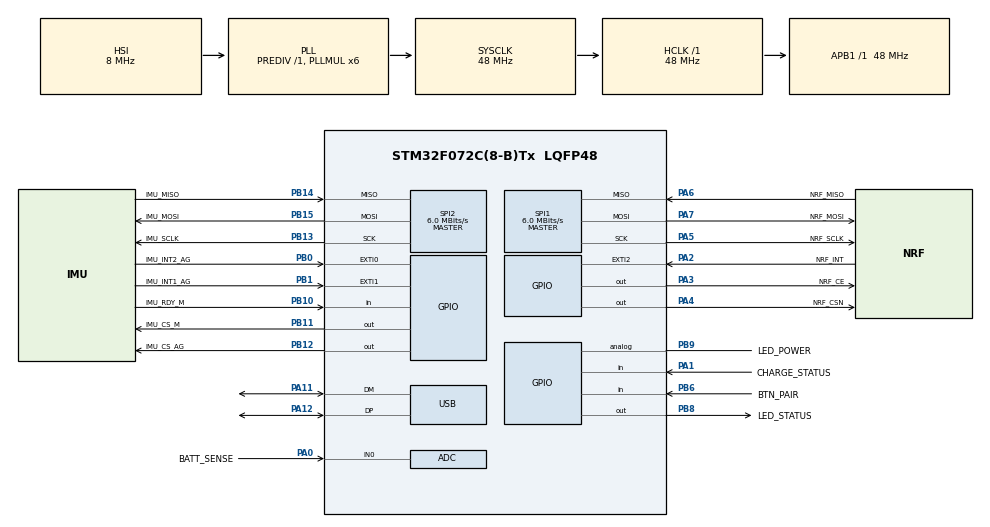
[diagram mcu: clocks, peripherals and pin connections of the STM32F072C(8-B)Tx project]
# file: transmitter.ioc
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Mcu.Family=STM32F0
Mcu.Name=STM32F072C(8-B)Tx
Mcu.Package=LQFP48
NVIC.USB_IRQn=true\:0\:0\:false\:false\:true\:false\:true
PA0.GPIO_Label=BATT_SENSE
PA0.Mode=IN0
PA0.Signal=ADC_IN0
PA1.GPIO_Label=CHARGE_STATUS
PA1.Signal=GPIO_Input
PA11.Mode=Device
PA11.Signal=USB_DM
PA12.Mode=Device
PA12.Signal=USB_DP
PA13.Mode=Serial_Wire
PA13.Signal=SYS_SWDIO
PA14.Mode=Serial_Wire
PA14.Signal=SYS_SWCLK
PA2.GPIO_Label=NRF_INT
PA2.Signal=GPXTI2
PA3.GPIO_Label=NRF_CE
PA3.Signal=GPIO_Output
PA4.GPIO_Label=NRF_CSN
PA4.Signal=GPIO_Output
PA5.GPIO_Label=NRF_SCLK
PA5.Mode=Full_Duplex_Master
PA5.Signal=SPI1_SCK
PA6.GPIO_Label=NRF_MISO
PA6.Mode=Full_Duplex_Master
PA6.Signal=SPI1_MISO
PA7.GPIO_Label=NRF_MOSI
PA7.Mode=Full_Duplex_Master
PA7.Signal=SPI1_MOSI
PB0.GPIO_Label=IMU_INT2_AG
PB0.Signal=GPXTI0
PB1.GPIO_Label=IMU_INT1_AG
PB1.Signal=GPXTI1
PB10.GPIO_Label=IMU_RDY_M
PB10.Signal=GPIO_Input
PB11.GPIO_Label=IMU_CS_M
PB11.Signal=GPIO_Output
PB12.GPIO_Label=IMU_CS_AG
PB12.Signal=GPIO_Output
PB13.GPIO_Label=IMU_SCLK
PB13.Mode=Full_Duplex_Master
PB13.Signal=SPI2_SCK
PB14.GPIO_Label=IMU_MISO
PB14.Mode=Full_Duplex_Master
PB14.Signal=SPI2_MISO
PB15.GPIO_Label=IMU_MOSI
PB15.Mode=Full_Duplex_Master
PB15.Signal=SPI2_MOSI
PB6.GPIO_Label=BTN_PAIR
PB6.GPIO_PuPd=GPIO_PULLDOWN
PB6.Signal=GPIO_Input
PB8.GPIO_Label=LED_STATUS
PB8.Signal=GPIO_Output
PB9.GPIO_Label=LED_POWER
PB9.Signal=GPIO_Analog
ProjectManager.HeapSize=0x200
ProjectManager.StackSize=0x400
ProjectManager.TargetToolchain=Other Toolchains (GPDSC)
RCC.AHBFreq_Value=48000000
RCC.APB1Freq_Value=48000000
RCC.APB1TimFreq_Value=48000000
RCC.HCLKFreq_Value=48000000
RCC.PLLMUL=RCC_PLL_MUL6
RCC.SYSCLKFreq_VALUE=48000000
RCC.SYSCLKSource=RCC_SYSCLKSOURCE_PLLCLK
RCC.VDD_VALUE=2.5
SPI1.BaudRatePrescaler=SPI_BAUDRATEPRESCALER_8
SPI1.CalculateBaudRate=6.0 MBits/s
SPI1.DataSize=SPI_DATASIZE_8BIT
SPI1.Direction=SPI_DIRECTION_2LINES
SPI1.Mode=SPI_MODE_MASTER
SPI1.VirtualType=VM_MASTER
SPI2.BaudRatePrescaler=SPI_BAUDRATEPRESCALER_8
SPI2.CalculateBaudRate=6.0 MBits/s
SPI2.DataSize=SPI_DATASIZE_8BIT
SPI2.Direction=SPI_DIRECTION_2LINES
SPI2.Mode=SPI_MODE_MASTER
SPI2.VirtualType=VM_MASTER
TIM2.Period=4294967295
TIM2.Prescaler=47
USB_DEVICE.CLASS_NAME_FS=DFU
USB_DEVICE.PID_DFU_FS=0xdf11
USB_DEVICE.VirtualMode=Dfu
USB_DEVICE.VirtualModeFS=Dfu_FS
VP_TIM2_VS_ClockSourceINT.Mode=Internal
VP_USB_DEVICE_VS_USB_DEVICE_DFU_FS.Mode=DFU_FS
board=custom

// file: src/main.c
/* USER CODE BEGIN Header */
/**
 ******************************************************************************
 * @file           : main.c
 * @brief          : Main program body
 ******************************************************************************
 * @attention
 *
 * <h2><center>&copy; Copyright (c) 2019 STMicroelectronics.
 * All rights reserved.</center></h2>
 *
 * This software component is licensed by ST under BSD 3-Clause license,
 * the "License"; You may not use this file except in compliance with the
 * License. You may obtain a copy of the License at:
 *                        opensource.org/licenses/BSD-3-Clause
 *
 ******************************************************************************
 */
/* USER CODE END Header */
#include "main.h"
#include "usb_device.h"

/* USER CODE BEGIN Includes */
#include "main_loop.hh"
/* USER CODE END Includes */

ADC_HandleTypeDef hadc;

SPI_HandleTypeDef hspi1;
SPI_HandleTypeDef hspi2;

TIM_HandleTypeDef htim2;

void        SystemClock_Config(void);
static void MX_GPIO_Init(void);
static void MX_SPI1_Init(void);
static void MX_SPI2_Init(void);
static void MX_ADC_Init(void);
static void MX_TIM2_Init(void);

/* USER CODE BEGIN 0 */
void dfu_run_bootloader()
{
  // set magic code 0xDEADBEEF
  // STM32 F072 has 16k SRAM in address 0x2000 0000 - 0x2000 3FFF
  *((unsigned long*)0x20003FF0) = 0xDEADBEEF;

  NVIC_SystemReset();
}
/* USER CODE END 0 */

int main(void)
{

  /* MCU Configuration--------------------------------------------------------*/

  /* Reset of all peripherals, Initializes the Flash interface and the Systick. */
  HAL_Init();

  /* Configure the system clock */
  SystemClock_Config();

  /* Initialize all configured peripherals */
  MX_GPIO_Init();
  MX_SPI1_Init();
  MX_SPI2_Init();
  MX_USB_DEVICE_Init();
  MX_ADC_Init();
  MX_TIM2_Init();
  /* USER CODE BEGIN 2 */

  main_loop(&hadc, &htim2, &hspi1, &hspi2);
  /* USER CODE END 2 */

  /* Infinite loop */

}

void SystemClock_Config(void)
{
  RCC_OscInitTypeDef       RCC_OscInitStruct = {0};
  RCC_ClkInitTypeDef       RCC_ClkInitStruct = {0};
  RCC_PeriphCLKInitTypeDef PeriphClkInit     = {0};

  /** Initializes the RCC Oscillators according to the specified parameters
   * in the RCC_OscInitTypeDef structure.
   */
  RCC_OscInitStruct.OscillatorType =
      RCC_OSCILLATORTYPE_HSI | RCC_OSCILLATORTYPE_HSI14 | RCC_OSCILLATORTYPE_HSI48;
  RCC_OscInitStruct.HSIState              = RCC_HSI_ON;
  RCC_OscInitStruct.HSI48State            = RCC_HSI48_ON;
  RCC_OscInitStruct.HSI14State            = RCC_HSI14_ON;
  RCC_OscInitStruct.HSICalibrationValue   = RCC_HSICALIBRATION_DEFAULT;
  RCC_OscInitStruct.HSI14CalibrationValue = 16;
  RCC_OscInitStruct.PLL.PLLState          = RCC_PLL_ON;
  RCC_OscInitStruct.PLL.PLLSource         = RCC_PLLSOURCE_HSI;
  RCC_OscInitStruct.PLL.PLLMUL            = RCC_PLL_MUL6;
  RCC_OscInitStruct.PLL.PREDIV            = RCC_PREDIV_DIV1;
  if (HAL_RCC_OscConfig(&RCC_OscInitStruct) != HAL_OK) {
    Error_Handler();
  }
  /** Initializes the CPU, AHB and APB buses clocks
   */
  RCC_ClkInitStruct.ClockType     = RCC_CLOCKTYPE_HCLK | RCC_CLOCKTYPE_SYSCLK | RCC_CLOCKTYPE_PCLK1;
  RCC_ClkInitStruct.SYSCLKSource  = RCC_SYSCLKSOURCE_PLLCLK;
  RCC_ClkInitStruct.AHBCLKDivider = RCC_SYSCLK_DIV1;
  RCC_ClkInitStruct.APB1CLKDivider = RCC_HCLK_DIV1;

  if (HAL_RCC_ClockConfig(&RCC_ClkInitStruct, FLASH_LATENCY_1) != HAL_OK) {
    Error_Handler();
  }
  PeriphClkInit.PeriphClockSelection = RCC_PERIPHCLK_USB;
  PeriphClkInit.UsbClockSelection    = RCC_USBCLKSOURCE_HSI48;

  if (HAL_RCCEx_PeriphCLKConfig(&PeriphClkInit) != HAL_OK) {
    Error_Handler();
  }
}

static void MX_ADC_Init(void)
{

  ADC_ChannelConfTypeDef sConfig = {0};

  /** Configure the global features of the ADC (Clock, Resolution, Data Alignment and number of
   * conversion)
   */
  hadc.Instance                   = ADC1;
  hadc.Init.ClockPrescaler        = ADC_CLOCK_ASYNC_DIV1;
  hadc.Init.Resolution            = ADC_RESOLUTION_12B;
  hadc.Init.DataAlign             = ADC_DATAALIGN_RIGHT;
  hadc.Init.ScanConvMode          = ADC_SCAN_DIRECTION_FORWARD;
  hadc.Init.EOCSelection          = ADC_EOC_SINGLE_CONV;
  hadc.Init.LowPowerAutoWait      = DISABLE;
  hadc.Init.LowPowerAutoPowerOff  = DISABLE;
  hadc.Init.ContinuousConvMode    = DISABLE;
  hadc.Init.DiscontinuousConvMode = DISABLE;
  hadc.Init.ExternalTrigConv      = ADC_SOFTWARE_START;
  hadc.Init.ExternalTrigConvEdge  = ADC_EXTERNALTRIGCONVEDGE_NONE;
  hadc.Init.DMAContinuousRequests = DISABLE;
  hadc.Init.Overrun               = ADC_OVR_DATA_PRESERVED;
  if (HAL_ADC_Init(&hadc) != HAL_OK) {
    Error_Handler();
  }
  /** Configure for the selected ADC regular channel to be converted.
   */
  sConfig.Channel      = ADC_CHANNEL_0;
  sConfig.Rank         = ADC_RANK_CHANNEL_NUMBER;
  sConfig.SamplingTime = ADC_SAMPLETIME_1CYCLE_5;
  if (HAL_ADC_ConfigChannel(&hadc, &sConfig) != HAL_OK) {
    Error_Handler();
  }
}

static void MX_SPI1_Init(void)
{

  /* SPI1 parameter configuration*/
  hspi1.Instance               = SPI1;
  hspi1.Init.Mode              = SPI_MODE_MASTER;
  hspi1.Init.Direction         = SPI_DIRECTION_2LINES;
  hspi1.Init.DataSize          = SPI_DATASIZE_8BIT;
  hspi1.Init.CLKPolarity       = SPI_POLARITY_LOW;
  hspi1.Init.CLKPhase          = SPI_PHASE_1EDGE;
  hspi1.Init.NSS               = SPI_NSS_SOFT;
  hspi1.Init.BaudRatePrescaler = SPI_BAUDRATEPRESCALER_8;
  hspi1.Init.FirstBit          = SPI_FIRSTBIT_MSB;
  hspi1.Init.TIMode            = SPI_TIMODE_DISABLE;
  hspi1.Init.CRCCalculation    = SPI_CRCCALCULATION_DISABLE;
  hspi1.Init.CRCPolynomial     = 7;
  hspi1.Init.CRCLength         = SPI_CRC_LENGTH_DATASIZE;
  hspi1.Init.NSSPMode          = SPI_NSS_PULSE_ENABLE;
  if (HAL_SPI_Init(&hspi1) != HAL_OK) {
    Error_Handler();
  }
}

static void MX_SPI2_Init(void)
{

  /* SPI2 parameter configuration*/
  hspi2.Instance               = SPI2;
  hspi2.Init.Mode              = SPI_MODE_MASTER;
  hspi2.Init.Direction         = SPI_DIRECTION_2LINES;
  hspi2.Init.DataSize          = SPI_DATASIZE_8BIT;
  hspi2.Init.CLKPolarity       = SPI_POLARITY_LOW;
  hspi2.Init.CLKPhase          = SPI_PHASE_1EDGE;
  hspi2.Init.NSS               = SPI_NSS_SOFT;
  hspi2.Init.BaudRatePrescaler = SPI_BAUDRATEPRESCALER_8;
  hspi2.Init.FirstBit          = SPI_FIRSTBIT_MSB;
  hspi2.Init.TIMode            = SPI_TIMODE_DISABLE;
  hspi2.Init.CRCCalculation    = SPI_CRCCALCULATION_DISABLE;
  hspi2.Init.CRCPolynomial     = 7;
  hspi2.Init.CRCLength         = SPI_CRC_LENGTH_DATASIZE;
  hspi2.Init.NSSPMode          = SPI_NSS_PULSE_ENABLE;
  if (HAL_SPI_Init(&hspi2) != HAL_OK) {
    Error_Handler();
  }
}

static void MX_TIM2_Init(void)
{

  TIM_ClockConfigTypeDef  sClockSourceConfig = {0};
  TIM_MasterConfigTypeDef sMasterConfig      = {0};

  htim2.Instance               = TIM2;
  htim2.Init.Prescaler         = 47;
  htim2.Init.CounterMode       = TIM_COUNTERMODE_UP;
  htim2.Init.Period            = 4294967295;
  htim2.Init.ClockDivision     = TIM_CLOCKDIVISION_DIV1;
  htim2.Init.AutoReloadPreload = TIM_AUTORELOAD_PRELOAD_DISABLE;
  if (HAL_TIM_Base_Init(&htim2) != HAL_OK) {
    Error_Handler();
  }
  sClockSourceConfig.ClockSource = TIM_CLOCKSOURCE_INTERNAL;
  if (HAL_TIM_ConfigClockSource(&htim2, &sClockSourceConfig) != HAL_OK) {
    Error_Handler();
  }
  sMasterConfig.MasterOutputTrigger = TIM_TRGO_RESET;
  sMasterConfig.MasterSlaveMode     = TIM_MASTERSLAVEMODE_DISABLE;
  if (HAL_TIMEx_MasterConfigSynchronization(&htim2, &sMasterConfig) != HAL_OK) {
    Error_Handler();
  }
}

static void MX_GPIO_Init(void)
{
  GPIO_InitTypeDef GPIO_InitStruct = {0};

  /* GPIO Ports Clock Enable */
  __HAL_RCC_GPIOA_CLK_ENABLE();
  __HAL_RCC_GPIOB_CLK_ENABLE();

  /*Configure GPIO pin Output Level */
  HAL_GPIO_WritePin(GPIOA, NRF_CE_Pin | NRF_CSN_Pin, GPIO_PIN_RESET);

  /*Configure GPIO pin Output Level */
  HAL_GPIO_WritePin(GPIOB, IMU_CS_M_Pin | IMU_CS_AG_Pin | LED_STATUS_Pin, GPIO_PIN_RESET);

  /*Configure GPIO pin : CHARGE_STATUS_Pin */
  GPIO_InitStruct.Pin  = CHARGE_STATUS_Pin;
  GPIO_InitStruct.Mode = GPIO_MODE_INPUT;
  GPIO_InitStruct.Pull = GPIO_NOPULL;
  HAL_GPIO_Init(CHARGE_STATUS_GPIO_Port, &GPIO_InitStruct);

  /*Configure GPIO pin : NRF_INT_Pin */
  GPIO_InitStruct.Pin  = NRF_INT_Pin;
  GPIO_InitStruct.Mode = GPIO_MODE_IT_RISING;
  GPIO_InitStruct.Pull = GPIO_NOPULL;
  HAL_GPIO_Init(NRF_INT_GPIO_Port, &GPIO_InitStruct);

  /*Configure GPIO pins : NRF_CE_Pin NRF_CSN_Pin */
  GPIO_InitStruct.Pin   = NRF_CE_Pin | NRF_CSN_Pin;
  GPIO_InitStruct.Mode  = GPIO_MODE_OUTPUT_PP;
  GPIO_InitStruct.Pull  = GPIO_NOPULL;
  GPIO_InitStruct.Speed = GPIO_SPEED_FREQ_LOW;
  HAL_GPIO_Init(GPIOA, &GPIO_InitStruct);

  /*Configure GPIO pin : IMU_RDY_M_Pin */
  GPIO_InitStruct.Pin  = IMU_RDY_M_Pin;
  GPIO_InitStruct.Mode = GPIO_MODE_INPUT;
  GPIO_InitStruct.Pull = GPIO_NOPULL;
  HAL_GPIO_Init(IMU_RDY_M_GPIO_Port, &GPIO_InitStruct);

  /*Configure GPIO pins : IMU_CS_M_Pin IMU_CS_AG_Pin LED_STATUS_Pin */
  GPIO_InitStruct.Pin   = IMU_CS_M_Pin | IMU_CS_AG_Pin | LED_STATUS_Pin;
  GPIO_InitStruct.Mode  = GPIO_MODE_OUTPUT_PP;
  GPIO_InitStruct.Pull  = GPIO_NOPULL;
  GPIO_InitStruct.Speed = GPIO_SPEED_FREQ_LOW;
  HAL_GPIO_Init(GPIOB, &GPIO_InitStruct);

  /*Configure GPIO pin : BTN_PAIR_Pin */
  GPIO_InitStruct.Pin  = BTN_PAIR_Pin;
  GPIO_InitStruct.Mode = GPIO_MODE_INPUT;
  GPIO_InitStruct.Pull = GPIO_PULLDOWN;
  HAL_GPIO_Init(BTN_PAIR_GPIO_Port, &GPIO_InitStruct);

  /*Configure GPIO pin : LED_POWER_Pin */
  GPIO_InitStruct.Pin  = LED_POWER_Pin;
  GPIO_InitStruct.Mode = GPIO_MODE_ANALOG;
  GPIO_InitStruct.Pull = GPIO_NOPULL;
  HAL_GPIO_Init(LED_POWER_GPIO_Port, &GPIO_InitStruct);
}

void Error_Handler(void)
{
}

#ifdef USE_FULL_ASSERT
/**
 * @brief  Reports the name of the source file and the source line number
 *         where the assert_param error has occurred.
 * @param  file: pointer to the source file name
 * @param  line: assert_param error line source number
 * @retval None
 */
void assert_failed(uint8_t* file, uint32_t line)
{
  /* USER CODE BEGIN 6 */
  /* User can add his own implementation to report the file name and line
     number,
     tex: printf("Wrong parameters value: file %s on line %d\r\n", file, line)
   */
  /* USER CODE END 6 */
}
#endif /* USE_FULL_ASSERT */

/************************ (C) COPYRIGHT STMicroelectronics *****END OF FILE****/
